# STM32F413 register map
File version: 1.9
CPU: CM4 r0p1, little endian, MPU, FPU, 4 interrupt priority bits
Registers are 32-bit, read-write, reset 0x0 unless marked. A register's access mark holds for its fields unless they carry their own. Offsets are from the block's base; [hi:lo] are bit positions; lines under a group give offsets from that group; {n}, {i} and the like mark numbered series.

## AES — Advanced encryption standard hardware accelerator
Base 0x50060000
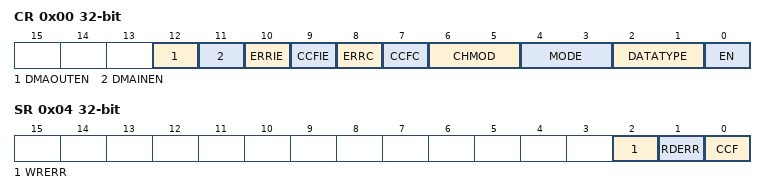
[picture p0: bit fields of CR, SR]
0x00 CR — control register
  [12] DMAOUTEN — Enable DMA management of data output phase
  [11] DMAINEN — Enable DMA management of data input phase
  [10] ERRIE — Error interrupt enable
  [9] CCFIE — CCF flag interrupt enable
  [8] ERRC — Error clear
  [7] CCFC — Computation Complete Flag Clear
  [6:5] CHMOD — AES chaining mode
  [4:3] MODE — AES operating mode
  [2:1] DATATYPE — Data type selection (for data in and data out to/from the cryptographic block)
  [0] EN — AES enable
0x04 SR ro — status register
  [2] WRERR — Write error flag
  [1] RDERR — Read error flag
  [0] CCF — Computation complete flag
0x08 DINR — data input register
  [31:0] AES_DINR — Data Input Register
0x0C DOUTR ro — data output register
  [31:0] AES_DOUTR — Data output register
0x10 KEYR0 — key register 0
  [31:0] AES_KEYR0 — Data Output Register (LSB key [31:0])
0x14 KEYR1 — key register 1
  [31:0] AES_KEYR1 — AES key register (key [63:32])
0x18 KEYR2 — key register 2
  [31:0] AES_KEYR2 — AES key register (key [95:64])
0x1C KEYR3 — key register 3
  [31:0] AES_KEYR3 — AES key register (MSB key [127:96])
0x20 IVR0 — initialization vector register 0
  [31:0] AES_IVR0 — initialization vector register (LSB IVR [31:0])
0x24 IVR1 — initialization vector register 1
  [31:0] AES_IVR1 — Initialization Vector Register (IVR [63:32])
0x28 IVR2 — initialization vector register 2
  [31:0] AES_IVR2 — Initialization Vector Register (IVR [95:64])
0x2C IVR3 — initialization vector register 3
  [31:0] AES_IVR3 — Initialization Vector Register (MSB IVR [127:96])

## ADC1 — Analog-to-digital converter
Base 0x40012000
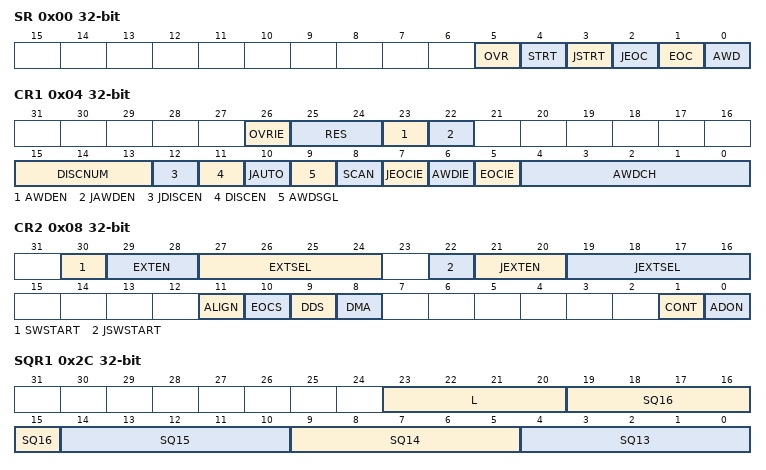
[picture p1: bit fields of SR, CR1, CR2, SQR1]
0x00 SR — status register
  [5] OVR write-0-clears — Overrun
  [4] STRT write-0-clears — Regular channel start flag
  [3] JSTRT write-0-clears — Injected channel start flag
  [2] JEOC write-0-clears — Injected channel end of conversion
  [1] EOC write-0-clears — Regular channel end of conversion
  [0] AWD write-0-clears — Analog watchdog flag
0x04 CR1 — control register 1
  [26] OVRIE — Overrun interrupt enable
  [25:24] RES — Resolution
  [23] AWDEN — Analog watchdog enable on regular channels
  [22] JAWDEN — Analog watchdog enable on injected channels
  [15:13] DISCNUM — Discontinuous mode channel count
  [12] JDISCEN — Discontinuous mode on injected channels
  [11] DISCEN — Discontinuous mode on regular channels
  [10] JAUTO — Automatic injected group conversion
  [9] AWDSGL — Enable the watchdog on a single channel in scan mode
  [8] SCAN — Scan mode
  [7] JEOCIE — Interrupt enable for injected channels
  [6] AWDIE — Analog watchdog interrupt enable
  [5] EOCIE — Interrupt enable for EOC
  [4:0] AWDCH — Analog watchdog channel select bits
0x08 CR2 — control register 2
  [30] SWSTART — Start conversion of regular channels
  [29:28] EXTEN — External trigger enable for regular channels
  [27:24] EXTSEL — External event select for regular group
  [22] JSWSTART — Start conversion of injected channels
  [21:20] JEXTEN — External trigger enable for injected channels
  [19:16] JEXTSEL — External event select for injected group
  [11] ALIGN — Data alignment
  [10] EOCS — End of conversion selection
  [9] DDS — DMA disable selection (for single ADC mode)
  [8] DMA — Direct memory access mode (for single ADC mode)
  [1] CONT — Continuous conversion
  [0] ADON — A/D Converter ON / OFF
0x0C SMPR1 — sample time register 1
  [31:0] SMPx_x — Sample time bits
0x10 SMPR2 — sample time register 2
  [31:0] SMPx_x — Sample time bits
{0x10+4i} JOFR{i} (i=1..4) — injected channel data offset register x
  [11:0] JOFFSET{i} — Data offset for injected channel x
0x24 HTR reset 0xFFF — watchdog higher threshold register
  [11:0] HT — Analog watchdog higher threshold
0x28 LTR — watchdog lower threshold register
  [11:0] LT — Analog watchdog lower threshold
0x2C SQR1 — regular sequence register 1
  [23:20] L — Regular channel sequence length
  [5n-61:5n-65] SQ{n} (n=13..16) — {n}th conversion in regular sequence
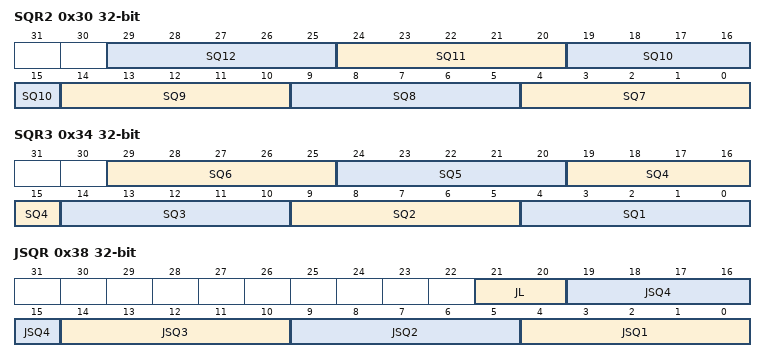
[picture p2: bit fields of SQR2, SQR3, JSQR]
0x30 SQR2 — regular sequence register 2
  [5n-31:5n-35] SQ{n} (n=7..12) — {n}th conversion in regular sequence
0x34 SQR3 — regular sequence register 3
  [29:25] SQ6 — 6th conversion in regular sequence
  [24:20] SQ5 — 5th conversion in regular sequence
  [19:15] SQ4 — 4th conversion in regular sequence
  [14:10] SQ3 — 3rd conversion in regular sequence
  [9:5] SQ2 — 2nd conversion in regular sequence
  [4:0] SQ1 — 1st conversion in regular sequence
0x38 JSQR — injected sequence register
  [21:20] JL — Injected sequence length
  [19:15] JSQ4 — 4th conversion in injected sequence
  [14:10] JSQ3 — 3rd conversion in injected sequence
  [9:5] JSQ2 — 2nd conversion in injected sequence
  [4:0] JSQ1 — 1st conversion in injected sequence
{0x38+4i} JDR{i} ro (i=1..4) — injected data register x
  [15:0] JDATA — Injected data
0x4C DR ro — regular data register
  [15:0] DATA — Regular data

## Notices in the file
Copyright (c) 2024 STMicroelectronics.
SPDX-License-Identifier: Apache-2.0
Licensed under the Apache License, Version 2.0 (the "License");
you may not use this file except in compliance with the License.
You may obtain a copy of the License at
http://www.apache.org/licenses/LICENSE-2.0
Unless required by applicable law or agreed to in writing, software
distributed under the License is distributed on an "AS IS" BASIS,
WITHOUT WARRANTIES OR CONDITIONS OF ANY KIND, either express or implied.
See the License for the specific language governing permissions and
limitations under the License.
